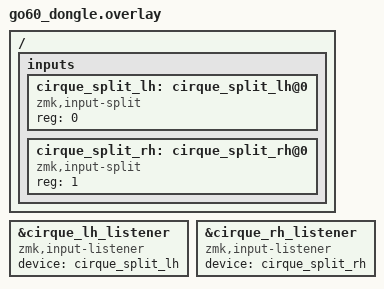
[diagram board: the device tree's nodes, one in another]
#include "go60_dongle.dtsi"

/ { 
    inputs {
    #address-cells = <1>;
    #size-cells = <0>;

        cirque_split_lh: cirque_split_lh@0 {
            compatible = "zmk,input-split";
            reg = <0>;
        };
    
        cirque_split_rh: cirque_split_rh@0 {
            compatible = "zmk,input-split";
            reg = <1>;
        };
    };
};

&cirque_lh_listener {
    compatible = "zmk,input-listener";
    status = "okay";
    device = <&cirque_split_lh>;
};

&cirque_rh_listener {
    compatible = "zmk,input-listener";
    status = "okay";
    device = <&cirque_split_rh>;
};
